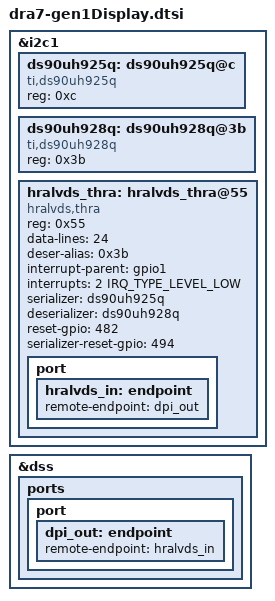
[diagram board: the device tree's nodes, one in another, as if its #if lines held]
#if defined HRALVDS_THRA_DISPLAY || defined HRALVDS_TJBA_DISPLAY

&i2c1 {
	ds90uh925q: ds90uh925q@c {
		compatible = "ti,ds90uh925q";
		reg = <0xc>;
		status = "okay";
	};

	ds90uh928q: ds90uh928q@3b {
		compatible = "ti,ds90uh928q";
		reg = <0x3b>;
		status = "okay";
	};

#if defined HRALVDS_THRA_DISPLAY

	hralvds_thra: hralvds_thra@55 {
		compatible = "hralvds,thra";
		reg = <0x55>;
		status = "okay";
		data-lines = <24>;
		deser-alias = <0x3b>;
		/* generated by the serializer */
		interrupt-parent = <&gpio1>;
		interrupts = <2 IRQ_TYPE_LEVEL_LOW>;

		/* driver can pick up i2c devices from here */
		serializer = <&ds90uh925q>;
		deserializer = <&ds90uh928q>;

		/* Display Controller (DISPC) reset line */
		reset-gpio = <482>;

		/* Serializer reset line (PWR_ON_LVDS) */
		serializer-reset-gpio = <494>;

		port {
			hralvds_in: endpoint {
				remote-endpoint = <&dpi_out>;
			};
		};
	};

#elif defined HRALVDS_TJBA_DISPLAY

	hralvds_tjba: hralvds_tjba@55 {
		compatible = "hralvds,tjba";
		reg = <0x55>;
		status = "okay";
		data-lines = <24>;
		deser-alias = <0x3b>;
		/* generated by the serializer */
		interrupt-parent = <&gpio1>;
		interrupts = <2 IRQ_TYPE_LEVEL_LOW>;

		/* driver can pick up i2c devices from here */
		serializer = <&ds90uh925q>;
		deserializer = <&ds90uh928q>;

		/* Display Controller (DISPC) reset line */
		reset-gpio = <482>;

		/* Serializer reset line (PWR_ON_LVDS) */
		serializer-reset-gpio = <494>;

		/* TJBA display strobed on the rising edge of the clock*/
		pixel_clock_rising_edge = "true";

		port {
			hralvds_in: endpoint {
				remote-endpoint = <&dpi_out>;
			};
		};
	};

#endif

};
&dss {
	ports {
		port {
			dpi_out: endpoint {
				remote-endpoint = <&hralvds_in>;
			};
		};
	};
};

#else

&i2c1{
	ds90uh925q: ds90uh925q@c {
		compatible = "ti,ds90uh925q";
		reg = <0x0c>;
		status = "okay";
	};

	ds90uh928q: ds90uh928q@3b {
		compatible = "ti,ds90uh928q";
		reg = <0x3b>;
		status = "okay";
	};
	max7310: max7310@1f {
		compatible = "maxim,max7310";
		reg = <0x1f>;
		status = "okay";
	};
	gt9271:gt9271@14 {
		compatible = "goodix,gt9271";
		status = "okay";
		reg = <0x14>;
		interrupt-parent = <&gpio1>;
		interrupts = <2 IRQ_TYPE_LEVEL_HIGH>;
		pinctrl-0 = <&tsc_pins>;
		max-touch-points = <10>;
		res-x = <1280>;
		res-y = <800>;
		tlc = <&tlc59108>;
	};

	tlc59108: tlc59108@40 {
		  compatible = "ti,tlc59108-lp101";
		  reg = <0x40>;
		  /* driver can pick up i2c devices from here */

		  deser-alias = <0x3b>;
		  serializer = <&ds90uh925q>;
		  deserializer = <&ds90uh928q>;
		  port-expander = <&max7310>;
		  gt9271-touch-sreen = <&gt9271>;
		  port {
			tlc_in: endpoint {
				remote-endpoint = <&dpi_out>;
			};
		  };
	};
};

&dss {
	ports {
		port {
			dpi_out: endpoint {
				remote-endpoint = <&tlc_in>;
			};
		};
	};
};

#endif
